# RS14100 register map
File version: 1.0
CPU: CM4 r0p1, little endian, MPU, FPU, 4 interrupt priority bits
Registers are 32-bit, read-write, reset 0x0 unless marked. A register's access mark holds for its fields unless they carry their own. Offsets are from the block's base; [hi:lo] are bit positions; {n}, {i} and the like mark numbered series; 'fields as' and 'values as' point back to an identical list.

## USART0 — Universal Asynchronous Receiver/Transmitter is for serial communication with peripherals, modems and datasets
Base 0x44000000
Same registers: ULP_UART 0x24041800, UART0 0x44000100, UART1 0x45020000
0x00 DLL — Divisor Latch Low
  [7:0] DLL — Lower 8-bits of a 16-bit, read/write, Divisor Latch register that contains the baud rate divisor for the UART.
0x00 THR wo (alternate view of DLL) — Transmit Holding Register
  [7:0] THR — Data to be transmitted on serial output port
0x00 RBR ro (alternate view of DLL) — Receive Buffer Register
  [7:0] RBR — Receive Buffer Field
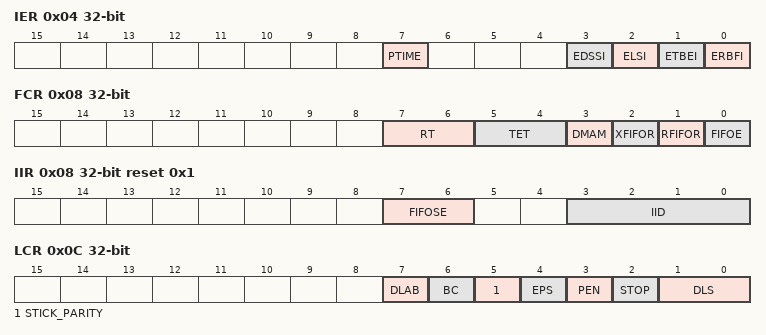
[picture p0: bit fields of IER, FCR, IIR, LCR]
0x04 IER — Interrupt Enable Register
  [7] PTIME — Programmable THRE Interrupt Mode Enable
    0=Disable (generation of THRE Interrupt is disabled); 1=Enable (generation of THRE Interrupt is enabled)
  [3] EDSSI — Enable Modem Status Interrupt
    0=Disable (Modem Status Interrupt is disabled); 1=Enable (Modem Status Interrupt is enabled)
  [2] ELSI — Enable Receiver Line Status Interrupt
    0=Disable (Receiver Line Status Interrupt is disabled); 1=Enable (Receiver Line Status Interrupt is enabled)
  [1] ETBEI — Enable Transmit Holding Register Empty Interrupt
    0=Disable (Transmit Holding Register Empty Interrupt is disabled); 1=Enable (Transmit Holding Register Empty Interrupt is enabled)
  [0] ERBFI — Enable Received Data Available Interrupt
    0=Disable (Received Data Available Interrupt is disabled); 1=Enable (Received Data Available Interrupt is enabled)
0x04 DLH (alternate view of IER) — Divisor Latch High
  [7:0] DLH — Upper 8-bits of a 16-bit, read/write, Divisor Latch register that contains the baud rate divisor for the UART
0x08 FCR wo — FIFO Control Register
  [7:6] RT — This is used to select the trigger level in the receiver FIFO at which the Received Data Available Interrupt is generated
    0=1 character in the FIFO; 1=FIFO 1/4 full; 2=FIFO 1/2 full; 3=FIFO 2 less than full
  [5:4] TET — TX Empty Trigger
    0=FIFO Empty; 1=2 characters in the FIFO; 2=FIFO 1/4 full; 3=FIFO 1/2 full
  [3] DMAM — DMA signalling mode
    0=Mode0 (DMA Signalling mode0); 1=Mode1 (DMA Signalling mode1)
  [2] XFIFOR — XMIT FIFO Reset
  [1] RFIFOR — RCVR FIFO Reset
  [0] FIFOE — This enables/disables the transmit (XMIT) and receive (RCVR) FIFOs
0x08 IIR ro reset 0x1 — Interrupt Identity Register
  [7:6] FIFOSE — This is used to indicate whether the FIFOs are enabled or disabled.
    0=Disable (FIFO is disabled); 1=Enable (FIFO is enabled)
  [3:0] IID — Interrupt ID
    0=modem status pending pending interrupt; 1=This field indicates no interrupt pending status; 2=Transmit Holding Register Empty pending interrupt; 4=Received Data Available pending interrupt; 6=Receive line status pending interrupt; 7=Busy detect pending interrupt; 12=Character Timeout pending interrupt
0x0C LCR — Line Control Register
  [7] DLAB — This bit is used to enable reading and writing of the Divisor Latch register to set the baud rate of the UART
    0=This bit must be cleared after initial baud rate set up
  [6] BC — This is used to cause a break condition to be transmitted to the receiving device
    0=LOGIC0 (If set to 1, the serial output is forced to the spacing (logic 0) state)
  [5] STICK_PARITY — This bit is used to force parity value
    0=LOGIC0 (When PEN, EPS, and Stick Parity are set to 1, the parity bit is transmitted and checked as logic 0); 1=LOGIC1 (If PEN and Stick Parity are set to 1 and EPS is a logic 0,then parity bit is transmitted and checked as a logic 1)
  [4] EPS — This is used to select between even and odd parity
    0=Set to 0 (An odd number of logic 1s is transmitted or checked); 1=Set to 1 (An even number of logic 1s is transmitted or checked)
  [3] PEN — This bit is used to enable and disable parity generation and detection in transmitted and received serial character
    0=Disable (Parity disabled); 1=Enable (Parity Enabled)
  [2] STOP — This is used to select the number of stop bits per character that the peripheral transmits and receives
    0=1 stop bit per character; 1=1.5 or 2 stop bits per character
  [1:0] DLS — Data Length Select,This is used to select the number of data bits per character that the peripheral transmits and receives
    {v}={v+5} bits per character (v=0..3)
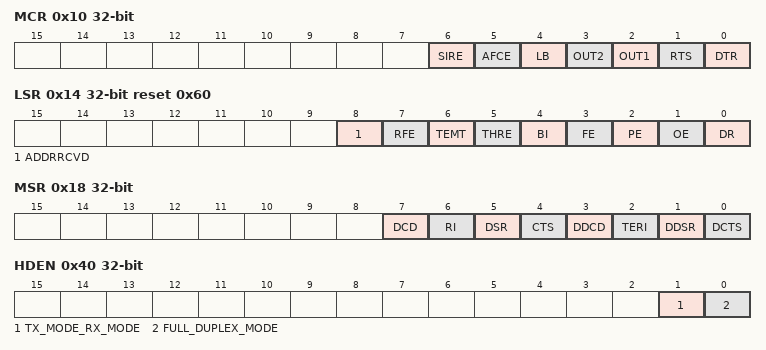
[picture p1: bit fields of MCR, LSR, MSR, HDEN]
0x10 MCR — Modem Control Register
  [6] SIRE — This is used to enable/disable the IrDA SIR Mode features
    0=Disabled (IrDA SIR Mode disabled); 1=Enabled (IrDA SIR Mode enabled)
  [5] AFCE — This is used to directly control the user-designated Output2 (out2_n) output
    0=Disabled (Auto Flow Control Mode disabled); 1=Enabled (Auto Flow Control Mode enabled)
  [4] LB — This is used to put the UART into a diagnostic mode for test purposes
  [3] OUT2 — This is used to directly control the user-designated Output2 (out2_n) output
    0=out2_n de-asserted (logic 1); 1=out2_n asserted (logic 0)
  [2] OUT1 — This is used to directly control the user-designated Output1 (out1_n) output
    0=out1_n de-asserted (logic 1); 1=out1_n asserted (logic 0)
  [1] RTS — This is used to directly control the Request to Send (rts_n) output
  [0] DTR — This is used to directly control the Data Terminal Ready (dtr_n) output
    0=dtr_n de-asserted (logic 1); 1=dtr_n asserted (logic 0)
0x14 LSR ro reset 0x60 — Line Status Register
  [8] ADDRRCVD — Address Received bit
  [7] RFE — This is used to indicate if there is at least one parity error,framing error, or break indication in the FIFO
    0=Disabled (no error in RX FIFO); 1=Enabled (error in RX FIFO)
  [6] TEMT — Transmitter Empty bit
  [5] THRE — Transmit Holding Register Empty bit
  [4] BI — his is used to indicate the detection of a break sequence on the serial input data
  [3] FE — This is used to indicate the occurrence of a framing error in the receiver
    0=Disabled (no framing error); 1=Enabled (framing error)
  [2] PE — This is used to indicate the occurrence of a parity error in the receiver if the Parity Enable (PEN) bit (LCR[3]) is set
    0=Disabled (no parity error); 1=Enabled (parity error)
  [1] OE — This is used to indicate the occurrence of an overrun error
    0=Disabled (no overrun error); 1=Enabled (overrun error)
  [0] DR — This is used to indicate that the receiver contains at least one character in the RBR or the receiver FIFO
    0=Disabled (No data Ready); 1=Enabled (Data Ready)
0x18 MSR ro — Modem Status Register
  [7] DCD — This is used to indicate the current state of the modem control line dcd_n
    0=Disabled (dcd_n input is de-asserted (logic 1)); 1=Enabled (dcd_n input is asserted (logic 0))
  [6] RI — This is used to indicate the current state of the modem control line ri_n
    0=Disabled (ri_n input is de-asserted (logic 1)); 1=Enabled (ri_n input is asserted (logic 0))
  [5] DSR — This is used to indicate the current state of the modem control line dsr_n
    0=Disabled (dsr_n input is de-asserted (logic 1)); 1=Enabled (dsr_n input is asserted (logic 0))
  [4] CTS — This is used to indicate the current state of the modem control line cts_n
    0=Disabled (cts_n input is de-asserted (logic 1)); 1=Enabled (cts_n input is asserted (logic 0))
  [3] DDCD — This is used to indicate that the modem control line dcd_n has changed since the last time the MSR was read
    0=Disabled (no change on dcd_n since last read of MSR); 1=Enabled (change on dcd_n since last read of MSR)
  [2] TERI — This is used to indicate that a change on the input ri_n(from an active-low to an inactive-high state) has occurred since the last time the MSR was read
    0=Disabled (no change on ri_n since last read of MSR); 1=Enabled (change on ri_n since last read of MSR)
  [1] DDSR — This is used to indicate that the modem control line dsr_n has changed since the last time the MSR was read
    0=Disabled (no change on dsr_n since last read of MSR); 1=Enabled (change on dsr_n since last read of MSR)
  [0] DCTS — This is used to indicate that the modem control line cts_n has changed since the last time the MSR was read
    0=Disabled (no change on cts_n since last read of MSR); 1=Enabled (change on cts_n since last read of MSR)
0x1C SCR — Scratch pad Register
  [7:0] SCRATCH_PAD — This register is for programmers to use as a temporary storage space. It has no defined purpose
0x20 LPDLL — Low Power Divisor Latch Low Register
  [7:0] LOW_POWER_DLL — This register makes up the lower 8-bits of a 16-bit, read/write, Low Power Divisor Latch register that contains the baud rate divisor for the UART, which must give a baud rate of 115.2K
0x24 LPDLH — Low Power Divisor Latch High Register
  [7:0] LOW_POWER_DLH — This register makes up the upper 8-bits of a 16-bit, read/write, Low Power Divisor Latch register that contains the baud rate divisor for the UART, which must give a baud rate of 115200
0x40 HDEN
  [1] TX_MODE_RX_MODE — This signal is valid when full_duplex_mode is disabled
    0=tx_mode; 1=rx_mode
  [0] FULL_DUPLEX_MODE
    1=ENABLE (Full duplex mode enable); 0=DISABLE (Full duplex mode disable)
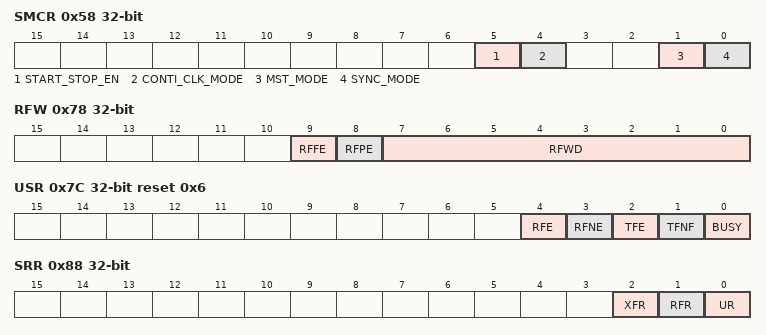
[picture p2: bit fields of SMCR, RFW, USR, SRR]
0x58 SMCR
  [5] START_STOP_EN
    1=Enable start stop; 0=Disable start stop
  [4] CONTI_CLK_MODE
    1=Continuous clock mode; 0=Non-continuous clock mode
  [1] MST_MODE
    1=MST mode; 0=Non-MST mode
  [0] SYNC_MODE
    1=Sync mode; 0=Non-Sync mode
0x70 FAR
  [0] SYNC_MODE
    0=disable (FIFO access mode disabled); 1=enable (FIFO access mode enabled)
0x74 TFR ro
  [7:0] TX_FIFO_RD — Transmit FIFO Read
0x78 RFW wo
  [9] RFFE — Receive FIFO Framing Error
  [8] RFPE — Receive FIFO Parity Error
  [7:0] RFWD — Receive FIFO Write Data
0x7C USR ro reset 0x6 — UART Status Register
  [4] RFE — To Indicate that the receive FIFO is completely full
    0=Disabled (Receive FIFO not full); 1=Enabled (Receive FIFO Full)
  [3] RFNE — To Indicate that the receive FIFO contains one or more entries
    0=Disabled (Receive FIFO is empty); 1=Enabled (Receive FIFO is not empty)
  [2] TFE — To Indicate that the transmit FIFO is completely empty
    0=Disabled (Transmit FIFO is not empty); 1=Enabled (Transmit FIFO is empty)
  [1] TFNF — To Indicate that the transmit FIFO is not full
    0=Disabled (Transmit FIFO is full); 1=Enabled (Transmit FIFO is not full)
  [0] BUSY — Indicates that a serial transfer is in progress
    0=Disabled (UART is idle or inactive); 1=Enabled (UART is busy (actively transferring data))
0x80 TFL ro — Transmit FIFO Level
  [29:0] FIFO_ADDR_WIDTH — Transmit FIFO Level. This is indicates the number of data entries in the transmit FIFO.
0x84 RFL ro — Receive FIFO Level
  [29:0] FIFO_ADDR_WIDTH — Receive FIFO Level. This is indicates the number of data entries in the receive FIFO.
0x88 SRR wo — Software Reset Register
  [2] XFR — XMIT FIFO Reset
  [1] RFR — RCVR FIFO Reset
  [0] UR — UART Reset
0x8C SRTS — Shadow Request to Send
  [0] SRTS — Shadow Request to Send.
0x90 SBCR — Shadow Break Control Register
  [0] SBCR — Shadow Break Control Bit
0x94 SDMAM — Shadow DMA Mode
  [0] SDMAM
    0=MODE0; 1=MODE1
0x98 SFE — Shadow FIFO Enable
  [0] SFE
0x9C SRT — Shadow RCVR Trigger
  [1:0] SRT
0xA0 STET — Shadow TX Empty Trigger
  [1:0] STET
0xA4 HTX — Halt Transmit
  [0] HALT_TX — This register is use to halt transmissions for testing
    0=Disabled (Halt TX disabled); 1=Enabled (Halt TX enabled)
0xA8 DMASA — DMA Software Acknowledge
  [0] DMA_SOFTWARE_ACK wo — This register is use to perform a DMA software acknowledge if a transfer needs to be terminated due to an error condition
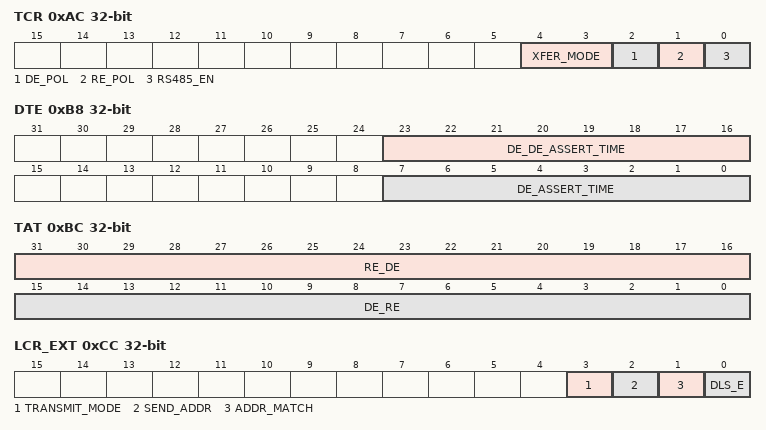
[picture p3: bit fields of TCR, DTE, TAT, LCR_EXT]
0xAC TCR — Transceiver Control Register.
  [4:3] XFER_MODE — Transfer Mode.
  [2] DE_POL — Driver Enable Polarity.
  [1] RE_POL — Receiver Enable Polarity.
  [0] RS485_EN — RS485 Transfer Enable.
0xB0 DE_EN — Driver Output Enable Register.
  [0] DE_EN — DE Enable control.
0xB4 RE_EN — Receiver Output Enable Register.
  [0] RE_EN — RE Enable control.
0xB8 DTE — Driver Output Enable Timing Register.
  [23:16] DE_DE_ASSERT_TIME — Driver enable de-assertion time.
  [7:0] DE_ASSERT_TIME — Driver enable assertion time.
0xBC TAT — TurnAround Timing Register
  [31:16] RE_DE — Receiver Enable to Driver Enable TurnAround time.
  [15:0] DE_RE — Driver Enable to Receiver Enable TurnAround time.
0xC0 DLF — Divisor Latch Fraction Register.
  [3:0] DLF — Fractional part of divisor.
0xC4 RAR — Receive Address Register.
  [7:0] RAR — This is an address matching register during receive mode.
0xC8 TAR — Transmit Address Register.
  fields as RAR
0xCC LCR_EXT — Line Extended Control Register
  [3] TRANSMIT_MODE — Transmit mode control bit.
  [2] SEND_ADDR — Send address control bit.
  [1] ADDR_MATCH — Address Match Mode.
  [0] DLS_E — Extension for DLS.
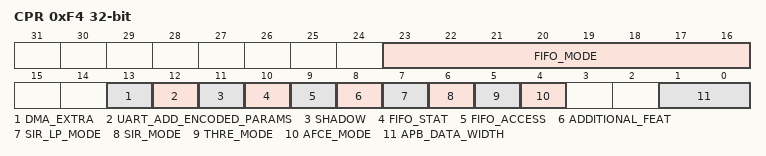
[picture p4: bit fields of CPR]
0xF4 CPR reset not defined — Component Parameter Register
  [23:16] FIFO_MODE ro, [13] DMA_EXTRA ro, [12] UART_ADD_ENCODED_PARAMS ro, [11] SHADOW ro, [10] FIFO_STAT ro, [9] FIFO_ACCESS ro, [8] ADDITIONAL_FEAT ro, [7] SIR_LP_MODE ro, [6] SIR_MODE ro, [5] THRE_MODE ro, [4] AFCE_MODE ro, [1:0] APB_DATA_WIDTH ro
0xF8 UCV ro — UART Component Version
  [31:0] UART_COMP_VER — ASCII value for each number in the version, followed by *
0xFC CTR ro reset 0x44570110 — Component Type Register
  [31:0] UART_COMP_VER — This register contains the peripherals identification code.
